# DDRSS0_CTL_CFG register map
Vendor: Texas Instruments
Registers are 32-bit, read-write, reset 0x0 unless marked. A register's access mark holds for its fields unless they carry their own. Offsets are as the file gives them; [hi:lo] are bit positions; lines under a group give offsets from that group; {n}, {i} and the like mark numbered series; 'fields as' and 'values as' point back to an identical list.

## DDRSS0_CTL_CFG (part 2 of 2)
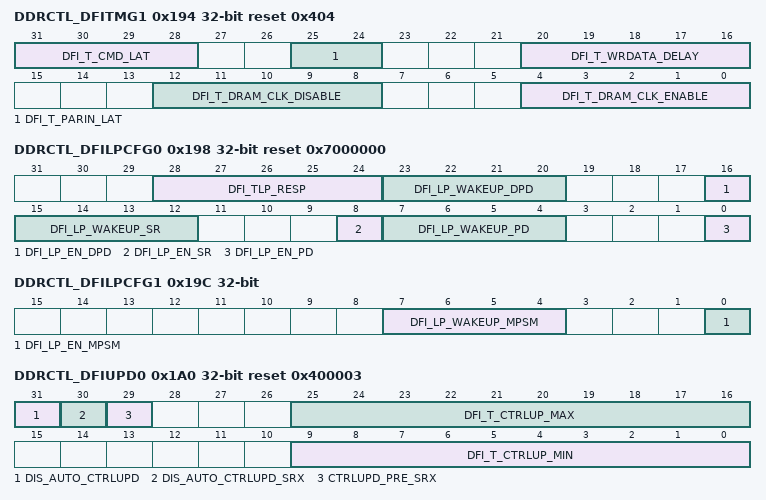
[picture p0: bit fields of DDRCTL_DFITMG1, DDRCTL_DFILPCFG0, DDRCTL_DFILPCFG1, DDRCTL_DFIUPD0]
0x194 DDRCTL_DFITMG1 reset 0x404 — DFI Timing Register 1
  [31:28] DFI_T_CMD_LAT — Specifies the number of 2 x DDRSS_CTL_CLK clock cycles between when the dfi_cs signal is asserted and when the associated command is driven.
  [25:24] DFI_T_PARIN_LAT — Specifies the number of 2 x DDRSS_CTL_CLK clock cycles between when the dfi_cs signal is asserted and when the associated dfi_parity_in signal is driven.
  [20:16] DFI_T_WRDATA_DELAY — Specifies the number of DDRSS_CTL_CLK clock cycles between when the dfi_wrdata_en signal is asserted and when the corresponding write data transfer is completed on the DRAM bus.
  [12:8] DFI_T_DRAM_CLK_DISABLE — Specifies the number of DDRSS_CTL_CLK clock cycles from the assertion of the dfi_dram_clk_disable signal on the DFI until the clock to the DRAM memory devices, at the PHY-DRAM boundary, maintains a low value.
  [4:0] DFI_T_DRAM_CLK_ENABLE — Specifies the number of DDRSS_CTL_CLK clock cycles from the de-assertion of the dfi_dram_clk_disable signal on the DFI until the first valid rising edge of the clock to the DRAM memory devices, at the PHY-DRAM boundary.
0x198 DDRCTL_DFILPCFG0 reset 0x7000000 — DFI Low Power Configuration Register 0
  [28:24] DFI_TLP_RESP — Setting in DDRSS_CTL_CLK clock cycles for DFI's tlp_resp time.
  [23:20] DFI_LP_WAKEUP_DPD — Value in DDRSS_CTL_CLK clock cycles to drive on dfi_lp_wakeup signal when Deep Power Down mode is entered.This is only present for designs supporting mDDR or LPDDR2/LPDDR3 devices.
  [16] DFI_LP_EN_DPD — Enables DFI Low Power interface handshaking during Deep Power Down Entry/Exit.This is only present for designs supporting mDDR or LPDDR2/LPDDR3 devices.
  [15:12] DFI_LP_WAKEUP_SR — Value in DFI clpck cycles to drive on dfi_lp_wakeup signal when Self Refresh mode is entered.
  [8] DFI_LP_EN_SR — Enables DFI Low Power interface handshaking during Self Refresh Entry/Exit.
  [7:4] DFI_LP_WAKEUP_PD — Value in DDRSS_CTL_CLK clock cycles to drive on dfi_lp_wakeup signal when Power Down mode is entered.
  [0] DFI_LP_EN_PD — Enables DFI Low Power interface handshaking during Power Down Entry/Exit.
0x19C DDRCTL_DFILPCFG1 — DFI Low Power Configuration Register 1
  [7:4] DFI_LP_WAKEUP_MPSM — Value in DDRSS_CTL_CLK clock cycles to drive on dfi_lp_wakeup signal when Maximum Power Saving Mode is entered.This is only present for designs supporting DDR4 devices.
  [0] DFI_LP_EN_MPSM — Enables DFI Low Power interface handshaking during Maximum Power Saving Mode Entry/Exit.
0x1A0 DDRCTL_DFIUPD0 reset 0x400003 — DFI Update Register 0
  [31] DIS_AUTO_CTRLUPD — When '1', disable the automatic dfi_ctrlupd_req generation by the DDR controller.
  [30] DIS_AUTO_CTRLUPD_SRX — When '1', disable the automatic dfi_ctrlupd_req generation by the DDR controller at self-refresh exit.
  [29] CTRLUPD_PRE_SRX — Selects dfi_ctrlupd_req requirements at SRX:0 - send ctrlupd after SRX1 - send ctrlupd before SRX If DDRCTL_DFIUPD0.dis_auto_ctrlupd_srx=1, this register has no impact, because no dfi_ctrlupd_req will be issued when SRX.
  [25:16] DFI_T_CTRLUP_MAX — Specifies the maximum number of DDRSS_CTL_CLK clock cycles that the dfi_ctrlupd_req signal can assert.
  [9:0] DFI_T_CTRLUP_MIN — Specifies the minimum number of DDRSS_CTL_CLK clock cycles that the dfi_ctrlupd_req signal must be asserted.
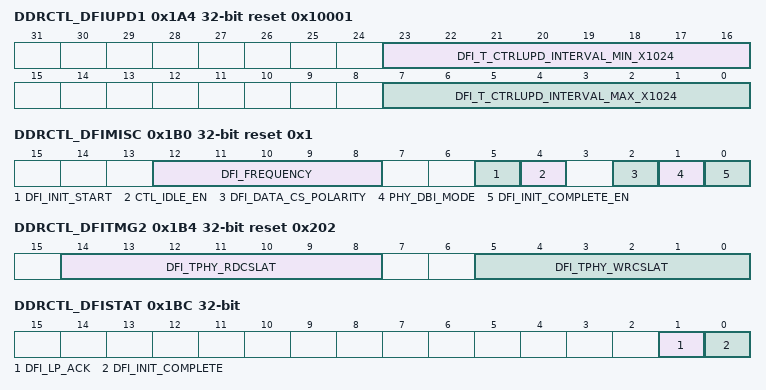
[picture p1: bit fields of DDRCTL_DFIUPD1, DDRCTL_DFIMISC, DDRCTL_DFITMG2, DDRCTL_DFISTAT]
0x1A4 DDRCTL_DFIUPD1 reset 0x10001 — DFI Update Register 1
  [23:16] DFI_T_CTRLUPD_INTERVAL_MIN_X1024 — This is the minimum amount of time between DDR controller initiated DFI update requests (which is executed whenever the DDR controller is idle).
  [7:0] DFI_T_CTRLUPD_INTERVAL_MAX_X1024 — This is the maximum amount of time between DDR controller initiated DFI update requests.
0x1A8 DDRCTL_DFIUPD2 reset 0x80000000 — DFI Update Register 2
  [31] DFI_PHYUPD_EN — Enables the support for acknowledging PHY-initiated updates:
0x1B0 DDRCTL_DFIMISC reset 0x1 — DFI Miscellaneous Control Register
  [12:8] DFI_FREQUENCY — Indicates the operating frequency of the system.
  [5] DFI_INIT_START — PHY init start request signal.
  [4] CTL_IDLE_EN — Enables support of ctl_idle signal, which is non-DFI related pin.
  [2] DFI_DATA_CS_POLARITY — Defines polarity of dfi_wrdata_cs and dfi_rddata_cs signals.0 - Signals are active low1 - Signals are active high
  [1] PHY_DBI_MODE — DBI implemented in DDRC or PHY.Present only in designs configured to support DDR4 and LPDDR4.
  [0] DFI_INIT_COMPLETE_EN — PHY initialization complete enable signal.
0x1B4 DDRCTL_DFITMG2 reset 0x202 — DFI Timing Register 2
  [14:8] DFI_TPHY_RDCSLAT — Number of 2 x DDRSS_CTL_CLK clock cycles between when a read command is sent on the DFI control interface and when the associated dfi_rddata_cs signal is asserted.
  [5:0] DFI_TPHY_WRCSLAT — Number of 2 x DDRSS_CTL_CLK clock cycles between when a write command is sent on the DFI control interface and when the associated dfi_wrdata_cs signal is asserted.
0x1B8 DDRCTL_DFITMG3 — DFI Timing Register 3
  [4:0] DFI_T_GEARDOWN_DELAY — The delay from dfi_geardown_en assertion to the time of the PHY being ready to receive commands.
0x1BC DDRCTL_DFISTAT ro — DFI Status Register
  [1] DFI_LP_ACK — Stores the value of the dfi_lp_ack input to the controller.
  [0] DFI_INIT_COMPLETE — The status flag register which announces when the DFI initialization has been completed.
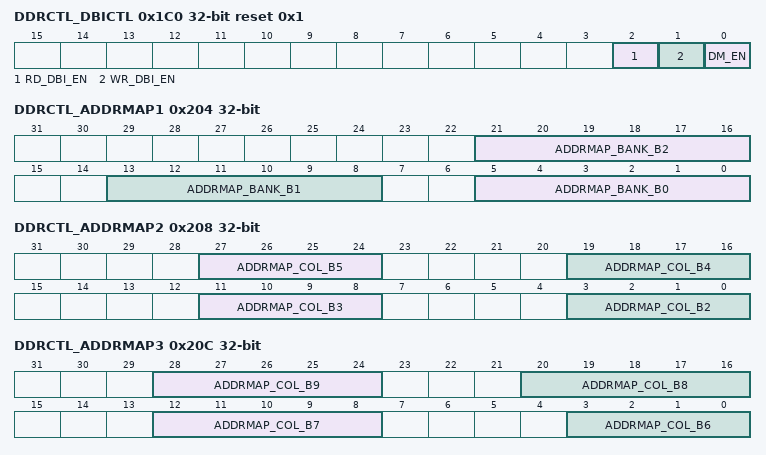
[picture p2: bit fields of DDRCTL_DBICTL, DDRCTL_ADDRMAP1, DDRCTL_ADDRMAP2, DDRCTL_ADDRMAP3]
0x1C0 DDRCTL_DBICTL reset 0x1 — DM/DBI Control Register
  [2] RD_DBI_EN — Read DBI enable signal in DDRC.
  [1] WR_DBI_EN — Write DBI enable signal in DDRC.
  [0] DM_EN — DM enable signal in DDRC.
0x1C4 DDRCTL_DFIPHYMSTR reset 0x1 — DFI PHY Master
  [0] DFI_PHYMSTR_EN — Enables the PHY Master Interface:
0x200 DDRCTL_ADDRMAP0 — Address Map Register 0
  [4:0] ADDRMAP_CS_BIT0 — Selects the HIF address bit used as rank address bit 0.Internal Base: 6The selected HIF address bit is determined by adding the internal base to the value of this field. If unused, set to 31 and then rank address bit 0 is set to 0.
0x204 DDRCTL_ADDRMAP1 — Address Map Register 1
  [21:16] ADDRMAP_BANK_B2 — Selects the HIF address bit used as bank address bit 2.The selected HIF address bit is determined by adding the internal base to the value of this field. If unused, set to 63 and then bank address bit 2 is set to 0.
  [13:8] ADDRMAP_BANK_B1 — Selects the HIF address bits used as bank address bit 1.The selected HIF address bit for each of the bank address bits is determined by adding the internal base to the value of this field. If unused, set to 63 and then bank address bit 1 is set to 0.
  [5:0] ADDRMAP_BANK_B0 — Selects the HIF address bits used as bank address bit 0.The selected HIF address bit for each of the bank address bits is determined by adding the internal base to the value of this field. If unused, set to 63 and then bank address bit 0 is set to 0.
0x208 DDRCTL_ADDRMAP2 — Address Map Register 2
  [27:24] ADDRMAP_COL_B5 — - Full bus width mode: Selects the HIF address bit used as column address bit 5.- Quarter bus width mode: Selects the HIF address bit used as column address bit 7.Valid Range: 0 to 7, and 15Internal Base: 5The selected HIF address bit is determined by adding the internal base to the value of this field. If unused, set to 15 and then this column address bit is set to 0.
  [19:16] ADDRMAP_COL_B4 — - Full bus width mode: Selects the HIF address bit used as column address bit 4.- Quarter bus width mode: Selects the HIF address bit used as column address bit 6.Valid Range: 0 to 7, and 15Internal Base: 4The selected HIF address bit is determined by adding the internal base to the value of this field. If unused, set to 15 and then this column address bit is set to 0.
  [11:8] ADDRMAP_COL_B3 — - Full bus width mode: Selects the HIF address bit used as column address bit 3.- Quarter bus width mode: Selects the HIF address bit used as column address bit 5.Valid Range: 0 to 7Internal Base: 3The selected HIF address bit is determined by adding the internal base to the value of this field.
  [3:0] ADDRMAP_COL_B2 — - Full bus width mode: Selects the HIF address bit used as column address bit 2.- Quarter bus width mode: Selects the HIF address bit used as column address bit 4.Valid Range: 0 to 7Internal Base: 2The selected HIF address bit is determined by adding the internal base to the value of this field.
0x20C DDRCTL_ADDRMAP3 — Address Map Register 3
  [28:24] ADDRMAP_COL_B9 — - Full bus width mode: Selects the HIF address bit used as column address bit 9.- Quarter bus width mode: Selects the HIF address bit used as column address bit 13 (11 in LPDDR2/LPDDR3 mode).Valid Range: 0 to 7, x, and 31. x indicate a valid value in inline ECC configuration.Internal Base: 9The selected HIF address bit is determined by adding the internal base to the value of this field. If unused, set to 31 and then this column address bit is set to 0.
  [20:16] ADDRMAP_COL_B8 — - Full bus width mode: Selects the HIF address bit used as column address bit 8.- Quarter bus width mode: Selects the HIF address bit used as column address bit 11 (10 in LPDDR2/LPDDR3 mode).Valid Range: 0 to 7, x, and 31. x indicate a valid value in inline ECC configuration.Internal Base: 8The selected HIF address bit is determined by adding the internal base to the value of this field. If unused, set to 31 and then this column address bit is set to 0.
  [12:8] ADDRMAP_COL_B7 — - Full bus width mode: Selects the HIF address bit used as column address bit 7.- Quarter bus width mode: Selects the HIF address bit used as column address bit 9.Internal Base: 7The selected HIF address bit is determined by adding the internal base to the value of this field. If unused, set to 31 and then this column address bit is set to 0. In Inline ECC configuration and ECC is enabled (DDRCTL_ECCCFG0.ecc_mode&gt;0), the highest 3 column address bits must map to the highest 3 valid HIF address bits. If column bit 7 is the third highest column address bit, it must map to the third highest valid HIF address bit. (x = the highest valid HIF address bit - 2 - internal base) if it is unused, set to 31.
  [3:0] ADDRMAP_COL_B6 — - Full bus width mode: Selects the HIF address bit used as column address bit 6.- Quarter bus width mode: Selects the HIF address bit used as column address bit 8.Valid Range: 0 to 7, and 15Internal Base: 6The selected HIF address bit is determined by adding the internal base to the value of this field. If unused, set to 15 and then this column address bit is set to 0.
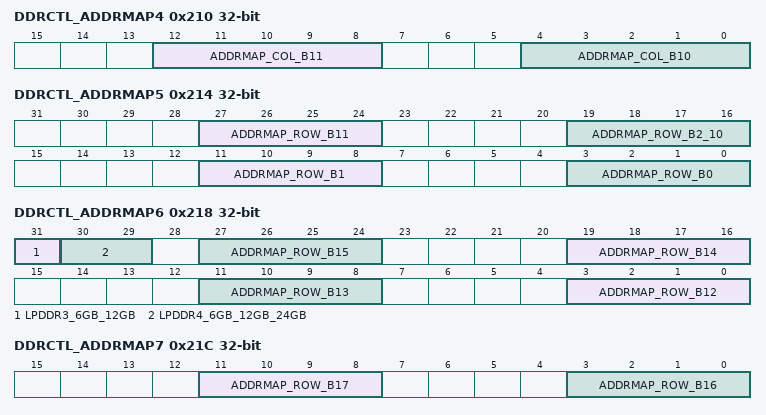
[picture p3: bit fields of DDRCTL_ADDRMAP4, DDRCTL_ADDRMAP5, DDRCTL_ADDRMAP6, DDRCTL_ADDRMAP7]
0x210 DDRCTL_ADDRMAP4 — Address Map Register 4
  [12:8] ADDRMAP_COL_B11 — - Full bus width mode: Selects the HIF address bit used as column address bit 13 (11 in LPDDR2/LPDDR3 mode).- Quarter bus width mode: Unused. To make it unused, this must be tied to 4'hF.Valid Range: 0 to 7, x, and 31. x indicate a valid value in inline ECC configuration.Internal Base: 11The selected HIF address bit is determined by adding the internal base to the value of this field. If unused, set to 31 and then this column address bit is set to 0.
  [4:0] ADDRMAP_COL_B10 — - Full bus width mode: Selects the HIF address bit used as column address bit 11 (10 in LPDDR2/LPDDR3 mode).- Quarter bus width mode: UNUSED. To make it unused, this must be tied to 4'hF.Valid Range: 0 to 7, x, and 31. x indicate a valid value in inline ECC configuration.The selected HIF address bit is determined by adding the internal base to the value of this field. If unused, set to 31 and then this column address bit is set to 0.
0x214 DDRCTL_ADDRMAP5 — Address Map Register 5
  [27:24] ADDRMAP_ROW_B11 — Selects the HIF address bit used as row address bit 11.The selected HIF address bit is determined by adding the internal base to the value of this field. If unused, set to 15 and then row address bit 11 is set to 0.
  [19:16] ADDRMAP_ROW_B2_10 — Selects the HIF address bits used as row address bits 2 to 10.Internal Base: 8 (for row address bit 2), 9 (for row address bit 3), 10 (for row address bit 4) etc increasing to 16 (for row address bit 10)The selected HIF address bit for each of the row address bits is determined by adding the internal base to the value of this field.
  [11:8] ADDRMAP_ROW_B1 — Selects the HIF address bits used as row address bit 1.Internal Base: 7The selected HIF address bit for each of the row address bits is determined by adding the internal base to the value of this field.
  [3:0] ADDRMAP_ROW_B0 — Selects the HIF address bits used as row address bit 0.Internal Base: 6The selected HIF address bit for each of the row address bits is determined by adding the internal base to the value of this field.
0x218 DDRCTL_ADDRMAP6 — Address Map Register 6
  [31] LPDDR3_6GB_12GB — Set this to 1 if there is an LPDDR3 SDRAM 6Gb or 12Gb device in use.
  [30:29] LPDDR4_6GB_12GB_24GB — Indicates what type of LPDDR4 SDRAM device is in use.
  [8n-93:8n-96] ADDRMAP_ROW_B{n} (n=12..15) — Selects the HIF address bit used as row address bit {n}.
0x21C DDRCTL_ADDRMAP7 — Address Map Register 7
  [11:8] ADDRMAP_ROW_B17 — Selects the HIF address bit used as row address bit 17.
  [3:0] ADDRMAP_ROW_B16 — Selects the HIF address bit used as row address bit 16.
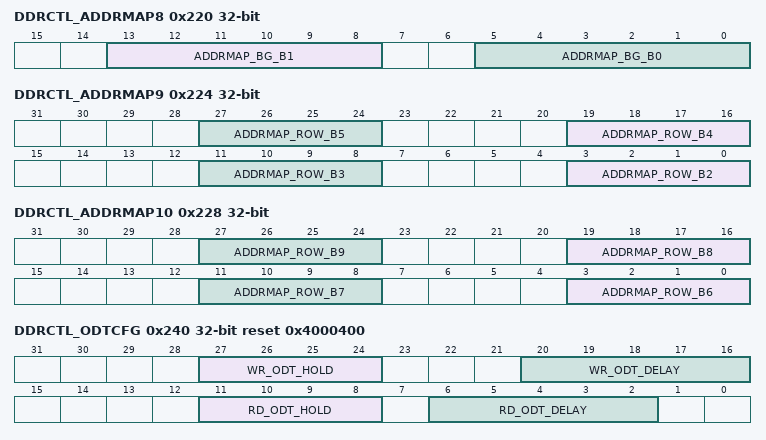
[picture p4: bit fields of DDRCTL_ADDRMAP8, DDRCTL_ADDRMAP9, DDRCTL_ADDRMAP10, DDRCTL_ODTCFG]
0x220 DDRCTL_ADDRMAP8 — Address Map Register 8
  [13:8] ADDRMAP_BG_B1 — Selects the HIF address bits used as bank group address bit 1.
  [5:0] ADDRMAP_BG_B0 — Selects the HIF address bits used as bank group address bit 0.
0x224 DDRCTL_ADDRMAP9 — Address Map Register 9
  [8n-13:8n-16] ADDRMAP_ROW_B{n} (n=2..5) — Selects the HIF address bits used as row address bit {n}.
0x228 DDRCTL_ADDRMAP10 — Address Map Register 10
  [8n-45:8n-48] ADDRMAP_ROW_B{n} (n=6..9) — Selects the HIF address bits used as row address bit {n}.
0x22C DDRCTL_ADDRMAP11 — Address Map Register 11
  [3:0] ADDRMAP_ROW_B10 — Selects the HIF address bits used as row address bit 10.
0x240 DDRCTL_ODTCFG reset 0x4000400 — ODT Configuration Register
  [27:24] WR_ODT_HOLD — 2 x DDRSS_CTL_CLK clock cycles to hold ODT for a write command.DDR2:- BL8: 0x5 (DDR2-400/533/667), 0x6 (DDR2-800), 0x7 (DDR2-1066)- BL4: 0x3 (DDR2-400/533/667), 0x4 (DDR2-800), 0x5 (DDR2-1066)DDR3:- BL8: 0x6DDR4:- BL8: 5 + WR_PREAMBLE + CRC_MODE WR_PREAMBLE = 1 (1tCK write preamble), 2 (2tCK write preamble) CRC_MODE = 0 (not CRC mode), 1 (CRC mode)LPDDR3:- BL8: 7 + RU(tODTon(max)/tCK)
  [20:16] WR_ODT_DELAY — The delay, in 2 x DDRSS_CTL_CLK clock cycles, from issuing a write command to setting ODT values associated with that command.DDR2:- CWL + AL - 3 (DDR2-400/533/667)- CWL + AL - 4 (DDR2-800)- CWL + AL - 5 (DDR2-1066)If (CWL + AL - 3 &lt; 0), DDR controller does not support ODT for write operation.DDR3: 0x0DDR4: DDRCTL_DFITMG1.dfi_t_cmd_lat (to adjust for CAL mode)LPDDR3: WL - 1 - RU(tODTon(max)/tCK)
  [11:8] RD_ODT_HOLD — 2 x DDRSS_CTL_CLK clock cycles to hold ODT for a read command.DDR2:- BL8: 0x6 (not DDR2-1066), 0x7 (DDR2-1066)- BL4: 0x4 (not DDR2-1066), 0x5 (DDR2-1066)DDR3:- BL8: 0x6DDR4:- BL8: 5 + RD_PREAMBLE RD_PREAMBLE = 1 (1tCK write preamble), 2 (2tCK write preamble)LPDDR3:- BL8: 5 + RU(tDQSCK(max)/tCK) - RD(tDQSCK(min)/tCK) + RU(tODTon(max)/tCK)
  [6:2] RD_ODT_DELAY — The delay, in 2 x DDRSS_CTL_CLK clock cycles, from issuing a read command to setting ODT values associated with that command.DDR2:- CL + AL - 4 (not DDR2-1066),- CL + AL - 5 (DDR2-1066)If (CL + AL - 4 &lt; 0), DDR controller does not support ODT for read operation.DDR3: CL - CWLDDR4: CL - CWL - RD_PREAMBLE + WR_PREAMBLE + DDRCTL_DFITMG1.dfi_t_cmd_lat (to adjust for CAL mode) WR_PREAMBLE = 1 (1tCK write preamble), 2 (2tCK write preamble) RD_PREAMBLE = 1 (1tCK write preamble), 2 (2tCK write preamble).If (CL - CWL - RD_PREAMBLE + WR_PREAMBLE) &lt; 0, DDR controller does not support ODT for read operation.LPDDR3: RL + RD(tDQSCK(min)/tCK) - 1 - RU(tODTon(max)/tCK)
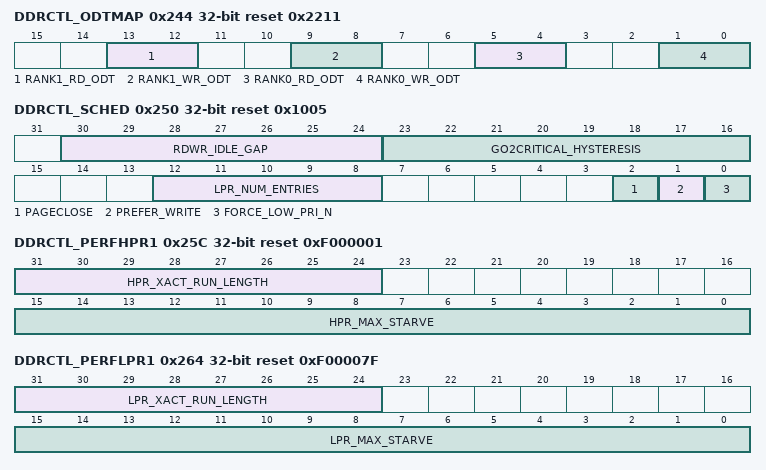
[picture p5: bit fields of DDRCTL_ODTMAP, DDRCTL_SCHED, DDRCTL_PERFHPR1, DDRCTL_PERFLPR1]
0x244 DDRCTL_ODTMAP reset 0x2211 — ODT/Rank Map Register
  [13:12] RANK1_RD_ODT — Indicates which remote ODTs must be turned on during a read from rank 1.
  [9:8] RANK1_WR_ODT — Indicates which remote ODTs must be turned on during a write to rank 1.
  [5:4] RANK0_RD_ODT — Indicates which remote ODTs must be turned on during a read from rank 0.
  [1:0] RANK0_WR_ODT — Indicates which remote ODTs must be turned on during a write to rank 0.
0x250 DDRCTL_SCHED reset 0x1005 — Scheduler Control Register
  [30:24] RDWR_IDLE_GAP — When the preferred transaction store is empty for these many clock cycles, switch to the alternate transaction store if it is non-empty.
  [23:16] GO2CRITICAL_HYSTERESIS — UNUSED
  [12:8] LPR_NUM_ENTRIES — Number of entries in the low priority transaction store is this value + 1.
  [2] PAGECLOSE — If true, bank is kept open only while there are page hit transactions available in the CAM to that bank.
  [1] PREFER_WRITE — If set then the bank selector prefers writes over reads.
  [0] FORCE_LOW_PRI_N — Active low signal.
0x254 DDRCTL_SCHED1 — Scheduler Control Register 1
  [7:0] PAGECLOSE_TIMER — This field works in conjunction with DDRCTL_SCHED.pageclose. It only has meaning if DDRCTL_SCHED.pageclose==1. If DDRCTL_SCHED.pageclose==1 and pageclose_timer==0, then an auto-precharge may be scheduled for last read or write command in the CAM with a bank and page hit.
0x25C DDRCTL_PERFHPR1 reset 0xF000001 — High Priority Read CAM Register 1
  [31:24] HPR_XACT_RUN_LENGTH — Number of transactions that are serviced once the HPR queue goes critical is the smaller of:- (a) This number- (b) Number of transactions available.
  [15:0] HPR_MAX_STARVE — Number of DDRSS_CTL_CLK clock cycles that the HPR queue can be starved before it goes critical.
0x264 DDRCTL_PERFLPR1 reset 0xF00007F — Low Priority Read CAM Register 1
  [31:24] LPR_XACT_RUN_LENGTH — Number of transactions that are serviced once the LPR queue goes critical is the smaller of:- (a) This number- (b) Number of transactions available.
  [15:0] LPR_MAX_STARVE — Number of DDRSS_CTL_CLK clock cycles that the LPR queue can be starved before it goes critical.
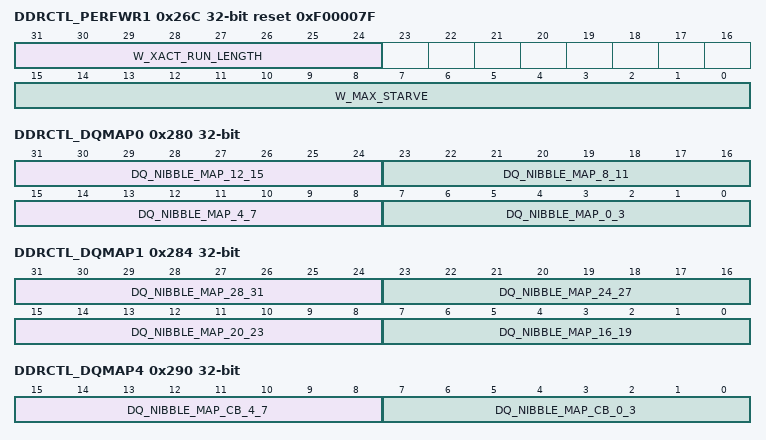
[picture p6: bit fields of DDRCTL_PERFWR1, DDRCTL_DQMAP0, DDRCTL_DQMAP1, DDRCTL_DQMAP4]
0x26C DDRCTL_PERFWR1 reset 0xF00007F — Write CAM Register 1
  [31:24] W_XACT_RUN_LENGTH — Number of transactions that are serviced once the WR queue goes critical is the smaller of:- (a) This number- (b) Number of transactions available.
  [15:0] W_MAX_STARVE — Number of DDRSS_CTL_CLK clock cycles that the WR queue can be starved before it goes critical.
0x280 DDRCTL_DQMAP0 — DQ Map Register 0
  [31:24] DQ_NIBBLE_MAP_12_15 — DQ nibble map for DQ bits [12-15] Present only in designs configured to support DDR4.
  [23:16] DQ_NIBBLE_MAP_8_11 — DQ nibble map for DQ bits [8-11] Present only in designs configured to support DDR4.
  [15:8] DQ_NIBBLE_MAP_4_7 — DQ nibble map for DQ bits [4-7] Present only in designs configured to support DDR4.
  [7:0] DQ_NIBBLE_MAP_0_3 — DQ nibble map for DQ bits [0-3] Present only in designs configured to support DDR4.
0x284 DDRCTL_DQMAP1 — DQ Map Register 1
  [31:24] DQ_NIBBLE_MAP_28_31 — DQ nibble map for DQ bits [28-31] Present only in designs configured to support DDR4.
  [23:16] DQ_NIBBLE_MAP_24_27 — DQ nibble map for DQ bits [24-27] Present only in designs configured to support DDR4.
  [15:8] DQ_NIBBLE_MAP_20_23 — DQ nibble map for DQ bits [20-23] Present only in designs configured to support DDR4.
  [7:0] DQ_NIBBLE_MAP_16_19 — DQ nibble map for DQ bits [16-19] Present only in designs configured to support DDR4.
0x290 DDRCTL_DQMAP4 — DQ Map Register 4
  [15:8] DQ_NIBBLE_MAP_CB_4_7 — DQ nibble map for DIMM ECC check bits [4-7] Present only in designs configured to support DDR4.
  [7:0] DQ_NIBBLE_MAP_CB_0_3 — DQ nibble map for DIMM ECC check bits [0-3] Present only in designs configured to support DDR4.
0x294 DDRCTL_DQMAP5 — DQ Map Register 5
  [0] DIS_DQ_RANK_SWAP — All even ranks have the same DQ mapping controled by DQMAP0-4 register as rank 0.1 - Disable rank based DQ swapping0 - Enable rank based DQ swapping Present only in designs configured to support DDR4.
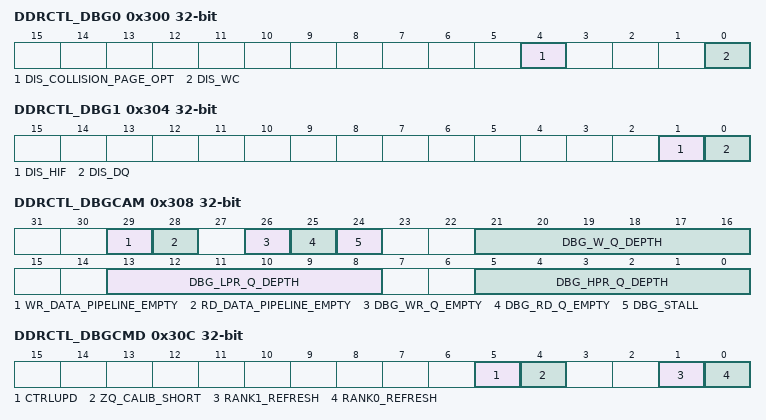
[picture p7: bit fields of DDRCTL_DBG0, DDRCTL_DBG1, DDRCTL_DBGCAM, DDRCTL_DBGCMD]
0x300 DDRCTL_DBG0 — Debug Register 0
  [4] DIS_COLLISION_PAGE_OPT — When this is set to '0', auto-precharge is disabled for the flushed command in a collision case.
  [0] DIS_WC — When 1, disable write combine.
0x304 DDRCTL_DBG1 — Debug Register 1
  [1] DIS_HIF — When 1, DDR controller asserts the HIF command signal hif_cmd_stall.
  [0] DIS_DQ — When 1, DDR controller will not de-queue any transactions from the CAM.
0x308 DDRCTL_DBGCAM ro — CAM Debug Register
  [29] WR_DATA_PIPELINE_EMPTY — This bit indicates that the write data pipeline on the DFI interface is empty.
  [28] RD_DATA_PIPELINE_EMPTY — This bit indicates that the read data pipeline on the DFI interface is empty.
  [26] DBG_WR_Q_EMPTY — When 1, all the Write command queues and Write data buffers inside DDRC are empty.
  [25] DBG_RD_Q_EMPTY — When 1, all the Read command queues and Read data buffers inside DDRC are empty.
  [24] DBG_STALL — Stall FOR DEBUG ONLY
  [21:16] DBG_W_Q_DEPTH — Write queue depth The last entry of WR queue is reserved for ECC SCRUB operation.
  [13:8] DBG_LPR_Q_DEPTH — Low priority read queue depth The last entry of Lpr queue is reserved for ECC SCRUB operation.
  [5:0] DBG_HPR_Q_DEPTH — High priority read queue depth FOR DEBUG ONLY
0x30C DDRCTL_DBGCMD access not given — Command Debug Register
  [5] CTRLUPD — Setting this register bit to 1 indicates to the DDR controller to issue a dfi_ctrlupd_req to the PHY. (access W1S)
  [4] ZQ_CALIB_SHORT — Setting this register bit to 1 indicates to the DDR controller to issue a ZQCS (ZQ calibration short)/MPC(ZQ calibration) command to the SDRAM. (access W1S)
  [1] RANK1_REFRESH — Setting this register bit to 1 indicates to the DDR controller to issue a refresh to rank 1. (access W1S)
  [0] RANK0_REFRESH — Setting this register bit to 1 indicates to the DDR controller to issue a refresh to rank 0. (access W1S)
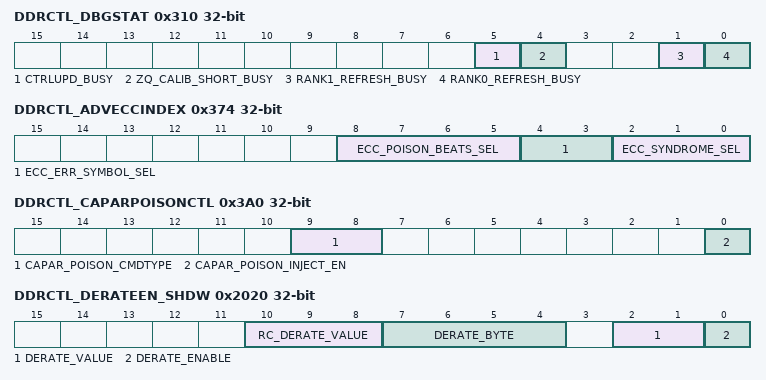
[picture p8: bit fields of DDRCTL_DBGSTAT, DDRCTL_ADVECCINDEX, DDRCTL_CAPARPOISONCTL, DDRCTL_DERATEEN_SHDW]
0x310 DDRCTL_DBGSTAT ro — Status Debug Register
  [5] CTRLUPD_BUSY — SoC core may initiate a ctrlupd operation only if this signal is low.
  [4] ZQ_CALIB_SHORT_BUSY — SoC core may initiate a ZQCS (ZQ calibration short) operation only if this signal is low.
  [1] RANK1_REFRESH_BUSY — SoC core may initiate a rank1_refresh operation (refresh operation to rank 1) only if this signal is low.
  [0] RANK0_REFRESH_BUSY — SoC core may initiate a rank0_refresh operation (refresh operation to rank 0) only if this signal is low.
0x320 DDRCTL_SWCTL reset 0x1 — Software Register Programming Control Enable
  [0] SW_DONE — Enable quasi-dynamic register programming outside reset.
0x324 DDRCTL_SWSTAT ro reset 0x1 — Software Register Programming Control Status
  [0] SW_DONE_ACK — Register programming done.
0x374 DDRCTL_ADVECCINDEX — Advanced ECC Index Register
  [8:5] ECC_POISON_BEATS_SEL — Selector of which DRAM beat's poison pattern will be set by DDRCTL_ECCPOISONPAT0/1/2 registers.4 DRAM beats can be poisoned. Set ecc_poison_beats_sel from 0~3 to set 1st to 4th beat's poison pattern. The other value is reserved.
  [4:3] ECC_ERR_SYMBOL_SEL — Selector of which error symbol's status output to ADVECCSTAT.
  [2:0] ECC_SYNDROME_SEL — Selector of which DRAM beat data output to DDRCTL_ECCCSYN0/1/2 as well as ECCUCSYN.
0x37C DDRCTL_ECCPOISONPAT0 — ECC Poison Pattern 0 Register
  [31:0] ECC_POISON_DATA_31_0 — Poison pattern for DRAM data[31:0].
0x384 DDRCTL_ECCPOISONPAT2 — ECC Poison Pattern 2 Register
  [7:0] ECC_POISON_DATA_71_64 — Poison pattern for DRAM data [71:64].
0x3A0 DDRCTL_CAPARPOISONCTL — CA parity poison contrl Register
  [9:8] CAPAR_POISON_CMDTYPE — Command type to be poisoned.
  [0] CAPAR_POISON_INJECT_EN — Setting this register bit to 1 triggers the CA parity poisoning.
0x3A4 DDRCTL_CAPARPOISONSTAT ro — CA parity poison status Register
  [0] CAPAR_POISON_COMPLETE — Indicates CA parity poisoning operation is done.
0x2020 DDRCTL_DERATEEN_SHDW — [FREQ1] Temperature Derate Enable Register
  [10:8] RC_DERATE_VALUE — Derate value of tRC for LPDDR4Present only in designs configured to support LPDDR4. The required number of cycles for derating can be determined by dividing 3.75ns by the core_ddrc_core_clk period, and rounding up the next integer.
  [7:4] DERATE_BYTE — Derate bytePresent only in designs configured to support LPDDR2/LPDDR3/LPDDR4. Indicates which byte of the MRR data is used for derating.
  [2:1] DERATE_VALUE — Derate valuePresent only in designs configured to support LPDDR2/LPDDR3/LPDDR4. Set to 0 for all LPDDR2 speed grades as derating value of +1.875 ns is less than a core_ddrc_core_clk period. For LPDDR3/4, if the period of core_ddrc_core_clk is less than 1.875ns, this register field should be set to 1 otherwise it should be set to 0.
  [0] DERATE_ENABLE — Enables derating
0x2024 DDRCTL_DERATEINT_SHDW reset 0x800000 — [FREQ1] Temperature Derate Interval Register
  [31:0] MR4_READ_INTERVAL — Interval between two MR4 reads, used to derate the timing parameters.
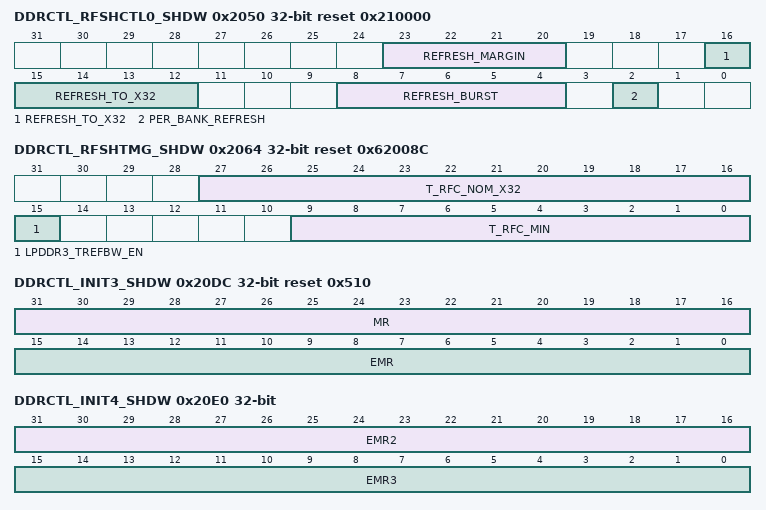
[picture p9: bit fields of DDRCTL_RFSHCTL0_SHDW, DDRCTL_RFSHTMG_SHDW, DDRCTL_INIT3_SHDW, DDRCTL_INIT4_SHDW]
0x2050 DDRCTL_RFSHCTL0_SHDW reset 0x210000 — [FREQ1] Refresh Control Register 0
  [23:20] REFRESH_MARGIN — Threshold value in number of DDRSS_CTL_CLK clock cycles before the critical refresh or page timer expires.
  [16:12] REFRESH_TO_X32 — If the refresh timer (tRFCnom, also known as tREFI) has expired at least once, but it has not expired (DDRCTL_RFSHCTL0.refresh_burst+1) times yet, then a speculative refresh may be performed. A speculative refresh is a refresh performed at a time when refresh would be useful, but before it is absolutely required.
  [8:4] REFRESH_BURST — The programmed value + 1 is the number of refresh timeouts that is allowed to accumulate before traffic is blocked and the refreshes are forced to execute.For information on burst refresh feature refer to section 3.9 of DDR2 JEDEC specification - JESD79-2F.pdf. For DDR2/3, the refresh is always per-rank and not per-bank. The rank refresh can be accumulated over 8*tREFI cycles using the burst refresh feature. In DDR4 mode, according to Fine Granularity feature, 8 refreshes can be postponed in 1X mode, 16 refreshes in 2X mode and 32 refreshes in 4X mode. If using PHY-initiated updates, care must be taken in the setting of DDRCTL_RFSHCTL0.refresh_burst, to ensure that tRFCmax is not violated due to a PHY-initiated update occurring shortly before a refresh burst was due. In this situation, the refresh burst will be delayed until the PHY-initiated update is complete.
  [2] PER_BANK_REFRESH — 1 - Per bank refresh
0x2064 DDRCTL_RFSHTMG_SHDW reset 0x62008C — [FREQ1] Refresh Timing Register
  [27:16] T_RFC_NOM_X32 — tREFI: Average time interval between refreshes per rank (Specification: 7.8us for DDR2, DDR3 and DDR4. See JEDEC specification for mDDR, LPDDR2, LPDDR3 and LPDDR4).For LPDDR2/LPDDR3/LPDDR4:- if using all-bank refreshes (DDRCTL_RFSHCTL0.per_bank_refresh = 0), this register should be set to tREFIab- if using per-bank refreshes (DDRCTL_RFSHCTL0.per_bank_refresh = 1), this register should be set to tREFIpb- Non-DDR4 or DDR4 Fixed 1x mode: DDRCTL_RFSHTMG.t_rfc_nom_x32 must be less than or equal to 0xFFE.Unit: Multiples of 32 clocks.
  [15] LPDDR3_TREFBW_EN — Used only when LPDDR3 memory type is connected.
  [9:0] T_RFC_MIN — tRFC (min): Minimum time from refresh to refresh or activate.In LPDDR2/LPDDR3/LPDDR4 mode:- if using all-bank refreshes, the tRFCmin value in the above equations is equal to tRFCab- if using per-bank refreshes, the tRFCmin value in the above equations is equal to tRFCpbIn DDR4 mode, the tRFCmin value in the above equations is different depending on the refresh mode (fixed 1X,2X,4X) and the device density.The user should program the appropriate value from the spec based on the 'refresh_mode' and the device density that is used. Unit: Clocks.
0x20DC DDRCTL_INIT3_SHDW reset 0x510 — [FREQ1] SDRAM Initialization Register 3
  [31:16] MR — DDR2: Value to write to MR register. Bit 8 is for DLL and the setting here is ignored. The DDR controller sets this bit appropriately.DDR3/DDR4: Value loaded into MR0 register.mDDR: Value to write to MR register.LPDDR2/LPDDR3/LPDDR4 - Value to write to MR1 register
  [15:0] EMR — DDR2: Value to write to EMR register. Bits 9:7 are for OCD and the setting in this register is ignored. The DDR controller sets those bits appropriately.DDR3/DDR4: Value to write to MR1 register Set bit 7 to 0. If PHY-evaluation mode training is enabled, this bit is set appropriately by the DDR controller during write leveling.mDDR: Value to write to EMR register.LPDDR2/LPDDR3/LPDDR4 - Value to write to MR2 register
0x20E0 DDRCTL_INIT4_SHDW — [FREQ1] SDRAM Initialization Register 4
  [31:16] EMR2 — DDR2: Value to write to EMR2 register.DDR3/DDR4: Value to write to MR2 registerLPDDR2/LPDDR3/LPDDR4: Value to write to MR3 register mDDR: Unused
  [15:0] EMR3 — DDR2: Value to write to EMR3 register.DDR3/DDR4: Value to write to MR3 registermDDR/LPDDR2/LPDDR3: UnusedLPDDR4: Value to write to MR13 register
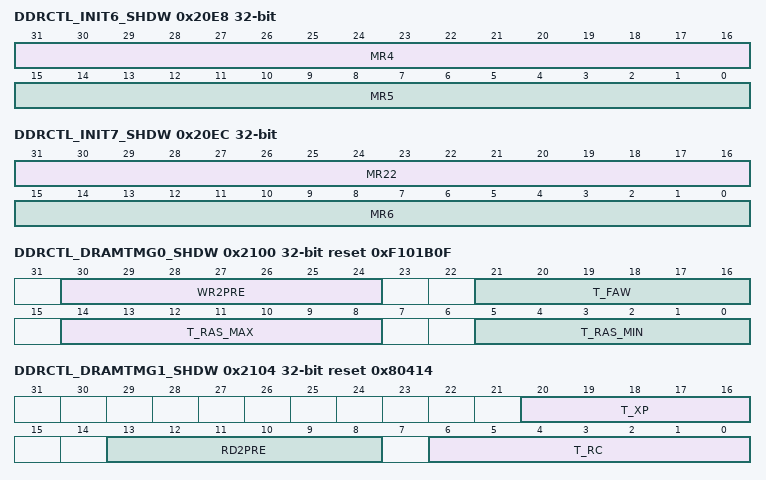
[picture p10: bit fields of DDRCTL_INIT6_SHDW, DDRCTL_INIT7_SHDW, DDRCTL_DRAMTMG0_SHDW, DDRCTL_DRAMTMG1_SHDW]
0x20E8 DDRCTL_INIT6_SHDW — [FREQ1] SDRAM Initialization Register 6
  [31:16] MR4 — DDR4 - Value to be loaded into SDRAM MR4 registers.
  [15:0] MR5 — DDR4 - Value to be loaded into SDRAM MR5 registers.
0x20EC DDRCTL_INIT7_SHDW — [FREQ1] SDRAM Initialization Register 7
  [31:16] MR22 — LPDDR4 - Value to be loaded into SDRAM MR22 registers.
  [15:0] MR6 — DDR4 - Value to be loaded into SDRAM MR6 registers.
0x2100 DDRCTL_DRAMTMG0_SHDW reset 0xF101B0F — [FREQ1] SDRAM Timing Register 0
  [30:24] WR2PRE — Minimum time between write and precharge to same bank.Specifications: WL + BL/2 + tWR = approximately 8 cycles + 15 ns = 14 clocks MHz and less for lower frequencies where:- WL = write latency- BL = burst length. This must match the value programmed in the BL bit of the mode register to the SDRAM. BST (burst terminate) is not supported at present.- tWR = Write recovery time. This comes directly from the SDRAM specification. Add one extra cycle for LPDDR2/LPDDR3/LPDDR4 for this parameter.
  [21:16] T_FAW — tFAW Valid only when 8 or more banks(or banks x bank groups) are present.
  [14:8] T_RAS_MAX — tRAS(max): Maximum time between activate and precharge to same bank.
  [5:0] T_RAS_MIN — tRAS(min): Minimum time between activate and precharge to the same bank.
0x2104 DDRCTL_DRAMTMG1_SHDW reset 0x80414 — [FREQ1] SDRAM Timing Register 1
  [20:16] T_XP — tXP: Minimum time after power-down exit to any operation.
  [13:8] RD2PRE — tRTP: Minimum time from read to precharge of same bank.Unit: Clocks.
  [6:0] T_RC — tRC: Minimum time between activates to same bank.
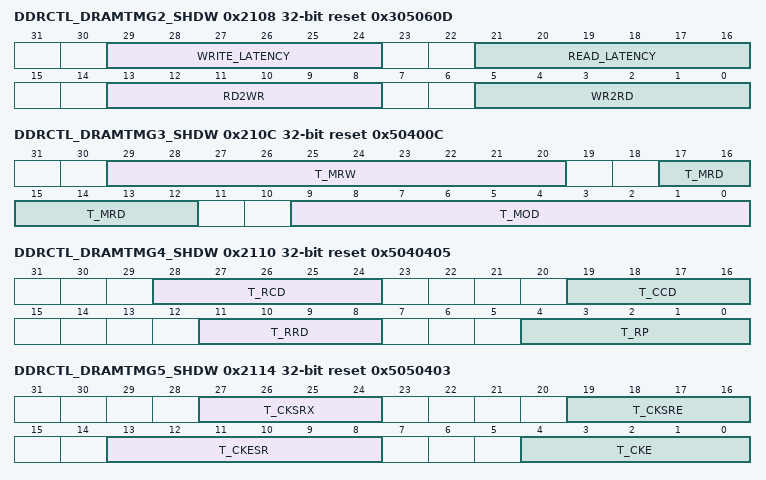
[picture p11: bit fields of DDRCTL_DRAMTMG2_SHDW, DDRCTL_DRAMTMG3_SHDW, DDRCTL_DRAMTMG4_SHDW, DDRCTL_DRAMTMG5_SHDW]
0x2108 DDRCTL_DRAMTMG2_SHDW reset 0x305060D — [FREQ1] SDRAM Timing Register 2
  [29:24] WRITE_LATENCY — Set to WL Time from write command to write data on SDRAM interface. This must be set to WL. For mDDR, it should normally be set to 1.
  [21:16] READ_LATENCY — Set to RL Time from read command to read data on SDRAM interface. This must be set to RL.
  [13:8] RD2WR — Minimum time from read command to write command.Include time for bus turnaround and all per-bank, per-rank, and global constraints.DDR2/3/mDDR: RL + BL/2 + 2 - WL DDR4: RL + BL/2 + 1 + WR_PREAMBLE - WLLPDDR2/LPDDR3: RL + BL/2 + RU(tDQSCKmax/tCK) + 1 - WL LPDDR4(DQ ODT is Disabled): RL + BL/2 + RU(tDQSCKmax/tCK) + WR_PREAMBLE + RD_POSTAMBLE - WLLPDDR4(DQ ODT is Enabled) : RL + BL/2 + RU(tDQSCKmax/tCK) + RD_POSTAMBLE - ODTLon - RU(tODTon(min)/tCK)Unit: Clocks.Where:- WL = write latency- BL = burst length. This must match the value programmed in the BL bit of the mode register to the SDRAM- RL = read latency = CAS latency - WR_PREAMBLE = write preamble. This is unique to DDR4 and LPDDR4.- RD_POSTAMBLE = read postamble. This is unique to LPDDR4. For LPDDR2/LPDDR3/LPDDR4, if derating is enabled (DDRCTL_DERATEEN.derate_enable=1), derated tDQSCKmax should be used.
  [5:0] WR2RD — In DDR4, minimum time from write command to read command for same bank group. In others, minimum time from write command to read command.Includes time for bus turnaround, recovery times, and all per-bank, per-rank, and global constraints.DDR4: CWL + PL + BL/2 + tWTR_LLPDDR2/3/4: WL + BL/2 + tWTR + 1Others: CWL + BL/2 + tWTRUnit: Clocks.Where:- CWL = CAS write latency- WL = Write latency- PL = Parity latency- BL = burst length. This must match the value programmed in the BL bit of the mode register to the SDRAM- tWTR_L = internal write to read command delay for same bank group. This comes directly from the SDRAM specification.- tWTR = internal write to read command delay. This comes directly from the SDRAM specification. Add one extra cycle for LPDDR2/LPDDR3/LPDDR4 operation.
0x210C DDRCTL_DRAMTMG3_SHDW reset 0x50400C — [FREQ1] SDRAM Timing Register 3
  [29:20] T_MRW — Time to wait after a mode register write or read (MRW or MRR).LPDDR2 typically requires value of 5.LPDDR3 typically requires value of 10.LPDDR4: Set this to the larger of tMRW and tMRWCKEL.For LPDDR2, this register is used for the time from a MRW/MRR to all other commands.
  [17:12] T_MRD — tMRD: Cycles to wait after a mode register write or read.DDR2/mDDR: Time from MRS to any commandDDR3/4: Time from MRS to MRS commandLPDDR2: not usedLPDDR3/4: Time from MRS to non-MRS command.
  [9:0] T_MOD — tMOD: Parameter used only in DDR3 and DDR4.
0x2110 DDRCTL_DRAMTMG4_SHDW reset 0x5040405 — [FREQ1] SDRAM Timing Register 4
  [28:24] T_RCD — tRCD - tAL: Minimum time from activate to read or write command to same bank.
  [19:16] T_CCD — DDR4: tCCD_L: This is the minimum time between two reads or two writes for same bank group.
  [11:8] T_RRD — DDR4: tRRD_L: Minimum time between activates from bank 'a' to bank 'b' for same bank group.
  [4:0] T_RP — tRP: Minimum time from precharge to activate of same bank.
0x2114 DDRCTL_DRAMTMG5_SHDW reset 0x5050403 — [FREQ1] SDRAM Timing Register 5
  [27:24] T_CKSRX — This is the time before Self Refresh Exit that CK is maintained as a valid clock before issuing SRX.
  [19:16] T_CKSRE — This is the time after Self Refresh Down Entry that CK is maintained as a valid clock.(*)Only if DDRCTL_CRCPARCTL1.caparity_disable_before_sr=0, this register should be increased by PL.
  [13:8] T_CKESR — Minimum CKE low width for Self refresh or Self refresh power down entry to exit timing in memory clock cycles.(*)Only if DDRCTL_CRCPARCTL1.caparity_disable_before_sr=0, this register should be increased by PL.
  [4:0] T_CKE — Minimum number of cycles of CKE HIGH/LOW during power-down and self refresh.
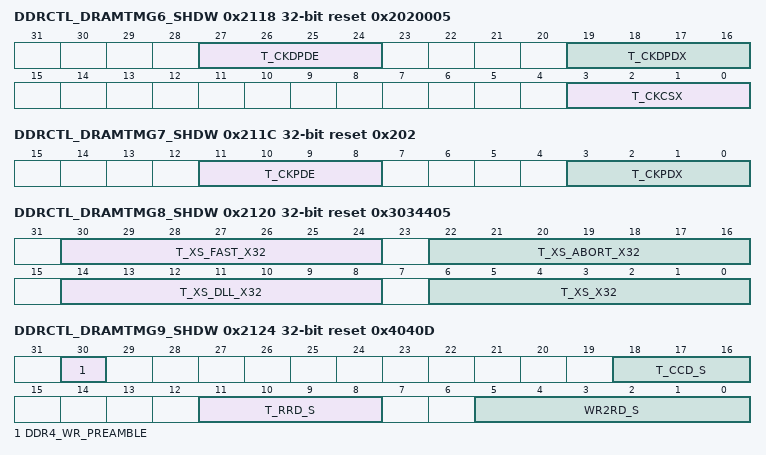
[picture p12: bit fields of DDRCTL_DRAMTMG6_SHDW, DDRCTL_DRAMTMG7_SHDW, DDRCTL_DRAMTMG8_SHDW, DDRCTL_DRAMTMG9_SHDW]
0x2118 DDRCTL_DRAMTMG6_SHDW reset 0x2020005 — [FREQ1] SDRAM Timing Register 6
  [27:24] T_CKDPDE — This is the time after Deep Power Down Entry that CK is maintained as a valid clock.
  [19:16] T_CKDPDX — This is the time before Deep Power Down Exit that CK is maintained as a valid clock before issuing DPDX.
  [3:0] T_CKCSX — This is the time before Clock Stop Exit that CK is maintained as a valid clock before issuing Clock Stop Exit.
0x211C DDRCTL_DRAMTMG7_SHDW reset 0x202 — [FREQ1] SDRAM Timing Register 7
  [11:8] T_CKPDE — This is the time after Power Down Entry that CK is maintained as a valid clock.
  [3:0] T_CKPDX — This is the time before Power Down Exit that CK is maintained as a valid clock before issuing PDX.
0x2120 DDRCTL_DRAMTMG8_SHDW reset 0x3034405 — [FREQ1] SDRAM Timing Register 8
  [30:24] T_XS_FAST_X32 — tXS_FAST: Exit Self Refresh to ZQCL, ZQCS and MRS (only CL, WR, RTP and Geardown mode).
  [22:16] T_XS_ABORT_X32 — tXS_ABORT: Exit Self Refresh to commands not requiring a locked DLL in Self Refresh Abort.
  [14:8] T_XS_DLL_X32 — tXSDLL: Exit Self Refresh to commands requiring a locked DLL.
  [6:0] T_XS_X32 — tXS: Exit Self Refresh to commands not requiring a locked DLL.
0x2124 DDRCTL_DRAMTMG9_SHDW reset 0x4040D — [FREQ1] SDRAM Timing Register 9
  [30] DDR4_WR_PREAMBLE — DDR4 Write preamble mode0 - 1tCK preamble1 - 2tCK preamble
  [18:16] T_CCD_S — tCCD_S: This is the minimum time between two reads or two writes for different bank group.
  [11:8] T_RRD_S — tRRD_S: Minimum time between activates from bank 'a' to bank 'b' for different bank group.
  [5:0] WR2RD_S — CWL + PL + BL/2 + tWTR_S Minimum time from write command to read command for different bank group.Where:- CWL = CAS write latency- PL = Parity latency- BL = burst length. This must match the value programmed in the BL bit of the mode register to the SDRAM- tWTR_S = internal write to read command delay for different bank group. This comes directly from the SDRAM specification.
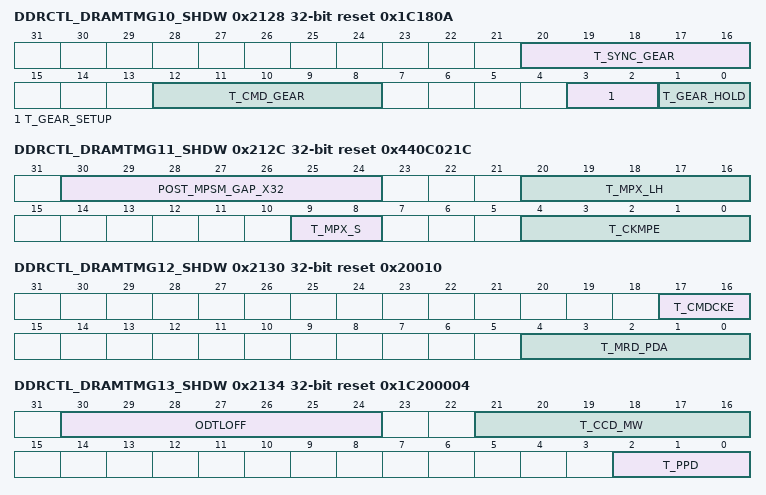
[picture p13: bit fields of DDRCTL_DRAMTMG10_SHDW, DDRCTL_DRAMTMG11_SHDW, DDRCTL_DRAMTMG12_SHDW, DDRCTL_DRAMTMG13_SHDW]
0x2128 DDRCTL_DRAMTMG10_SHDW reset 0x1C180A — [FREQ1] SDRAM Timing Register 10
  [20:16] T_SYNC_GEAR — Indicates the time between MRS command and the sync pulse time.
  [12:8] T_CMD_GEAR — Sync pulse to first valid command.
  [3:2] T_GEAR_SETUP — Geardown setup time.
  [1:0] T_GEAR_HOLD — Geardown hold time.
0x212C DDRCTL_DRAMTMG11_SHDW reset 0x440C021C — [FREQ1] SDRAM Timing Register 11
  [30:24] POST_MPSM_GAP_X32 — tXMPDLL: This is the minimum Exit MPSM to commands requiring a locked DLL.
  [20:16] T_MPX_LH — tMPX_LH: This is the minimum CS_n Low hold time to CKE rising edge.
  [9:8] T_MPX_S — tMPX_S: Minimum time CS setup time to CKE.
  [4:0] T_CKMPE — tCKMPE: Minimum valid clock requirement after MPSM entry.
0x2130 DDRCTL_DRAMTMG12_SHDW reset 0x20010 — [FREQ1] SDRAM Timing Register 12
  [17:16] T_CMDCKE — tCMDCKE: Delay from valid command to CKE input LOW.
  [4:0] T_MRD_PDA — tMRD_PDA: This is the Mode Register Set command cycle time in PDA mode.
0x2134 DDRCTL_DRAMTMG13_SHDW reset 0x1C200004 — [FREQ1] SDRAM Timing Register 13
  [30:24] ODTLOFF — LPDDR4: tODTLoff: This is the latency from CAS-2 command to tODToff reference.
  [21:16] T_CCD_MW — LPDDR4: tCCDMW: This is the minimum time from write or masked write to masked write command for same bank.
  [2:0] T_PPD — LPDDR4: tPPD: This is the minimum time from precharge to precharge command.
0x2138 DDRCTL_DRAMTMG14_SHDW reset 0xA0 — [FREQ1] SDRAM Timing Register 14
  [11:0] T_XSR — tXSR: Exit Self Refresh to any command.
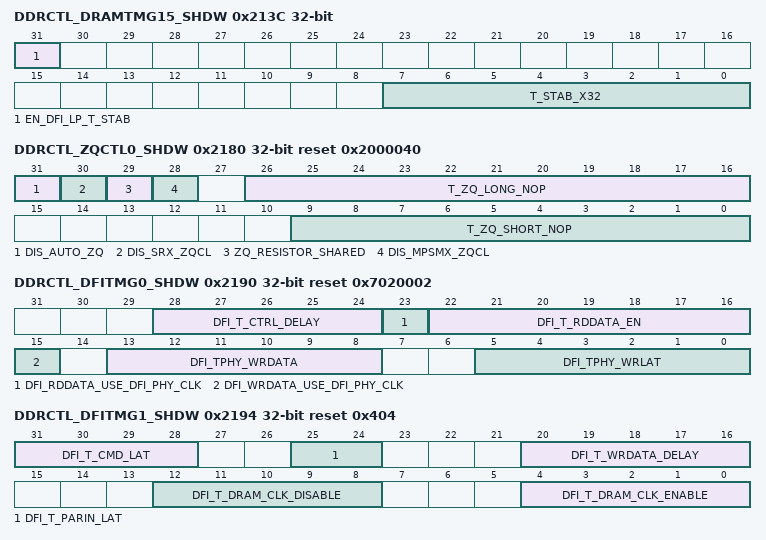
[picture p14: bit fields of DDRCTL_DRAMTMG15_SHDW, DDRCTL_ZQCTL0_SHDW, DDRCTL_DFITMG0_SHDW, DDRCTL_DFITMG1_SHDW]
0x213C DDRCTL_DRAMTMG15_SHDW — [FREQ1] SDRAM Timing Register 15
  [31] EN_DFI_LP_T_STAB — 1 - Enable using tSTAB when exiting DFI LP. Needs to be set when the PHY is stopping the clock during DFI LP to save maximum power.
  [7:0] T_STAB_X32 — tSTAB: Stabilization time.- when exiting power saving mode, if the clock was stopped, after re-enabling it the clock must be stable for a time specified by tSTAB- in the case of input clock frequency change (DDR4)- after issuing control words that refers to clock timing (Specification: 6us for DDR3, 5us for DDR4)
0x2180 DDRCTL_ZQCTL0_SHDW reset 0x2000040 — [FREQ1] ZQ Control Register 0
  [31] DIS_AUTO_ZQ — 1 - Disable DDR controller generation of ZQCS/MPC(ZQ calibration) command. Register DDRCTL_DBGCMD.zq_calib_short can be used instead to issue ZQ calibration request from APB module.
  [30] DIS_SRX_ZQCL — 1 - Disable issuing of ZQCL/MPC(ZQ calibration) command at Self-Refresh/SR-Powerdown exit. Only applicable when run in DDR3 or DDR4 or LPDDR2 or LPDDR3 or LPDDR4 mode.
  [29] ZQ_RESISTOR_SHARED — 1 - Denotes that ZQ resistor is shared between ranks. Means ZQinit/ZQCL/ZQCS/MPC(ZQ calibration) commands are sent to one rank at a time with tZQinit/tZQCL/tZQCS/tZQCAL/tZQLAT timing met between commands so that commands to different ranks do not overlap.
  [28] DIS_MPSMX_ZQCL — 1 - Disable issuing of ZQCL command at Maximum Power Saving Mode exit. Only applicable when run in DDR4 mode.
  [26:16] T_ZQ_LONG_NOP — tZQoper for DDR3/DDR4, tZQCL for LPDDR2/LPDDR3, tZQCAL for LPDDR4: Number of DDRSS_CTL_CLK clock cycles of NOP required after a ZQCL (ZQ calibration long)/MPC(ZQ Start) command is issued to SDRAM.DDR3/DDR4: program this to tZQoper/2 and round it up to the next integer value.LPDDR2/LPDDR3: program this to tZQCL/2 and round it up to the next integer value.LPDDR4: program this to tZQCAL/2 and round it up to the next integer value. This is only present for designs supporting DDR3/DDR4 or LPDDR2/LPDDR3/LPDDR4 devices.
  [9:0] T_ZQ_SHORT_NOP — tZQCS for DDR3/DD4/LPDDR2/LPDDR3, tZQLAT for LPDDR4: Number of DDRSS_CTL_CLK clock cycles of NOP required after a ZQCS (ZQ calibration short)/MPC(ZQ Latch) command is issued to SDRAM.
0x2190 DDRCTL_DFITMG0_SHDW reset 0x7020002 — [FREQ1] DFI Timing Register 0
  [28:24] DFI_T_CTRL_DELAY — Specifies the number of DDRSS_CTL_CLK clock cycles after an assertion or de-assertion of the DFI control signals that the control signals at the PHY-DRAM interface reflect the assertion or de-assertion.
  [23] DFI_RDDATA_USE_DFI_PHY_CLK — Defines whether dfi_rddata_en/dfi_rddata/dfi_rddata_valid is generated using HDR (DDRSS_CTL_CLK clock) or SDR (2 x DDRSS_CTL_CLK clock) values.- 0 in terms of HDR (DDRSS_CTL_CLK clock) cycles- 1 in terms of SDR (2 x DDRSS_CTL_CLK clock) cyclesIf using a DWC DDR3/2 PHY, DWC DDR2/3-Lite/mDDR PHY, DWC DDR multiPHY or DWC Gen2 DDR multiPHY, this field must be set to 0 otherwise, it must be set to 1.Programming Mode: Static
  [22:16] DFI_T_RDDATA_EN — Time from the assertion of a read command on the DFI interface to the assertion of the dfi_rddata_en signal. This corresponds to the DFI parameter trddata_en.
  [15] DFI_WRDATA_USE_DFI_PHY_CLK — Defines whether dfi_wrdata_en/dfi_wrdata/dfi_wrdata_mask is generated using HDR (DDRSS_CTL_CLK clock) or SDR (2 x DDRSS_CTL_CLK clock) values Selects whether value in DDRCTL_DFITMG0. dfi_tphy_wrlat is in terms of HDR (DDRSS_CTL_CLK clock) or SDR (2 x DDRSS_CTL_CLK clock) cycles Selects whether value in DDRCTL_DFITMG0.dfi_tphy_wrdata is in terms of HDR (DDRSS_CTL_CLK clock) or SDR (2 x DDRSS_CTL_CLK clock) cycles- 0 in terms of HDR (DDRSS_CTL_CLK clock) cycles- 1 in terms of SDR (2 x DDRSS_CTL_CLK clock) cyclesIf using a DWC DDR3/2 PHY, DWC DDR2/3-Lite/mDDR PHY, DWC DDR multiPHY or DWC Gen2 DDR multiPHY, this field must be set to 0 otherwise, it must be set to 1.Programming Mode: Static
  [13:8] DFI_TPHY_WRDATA — Specifies the number of clock cycles between when dfi_wrdata_en is asserted to when the associated write data is driven on the dfi_wrdata signal.
  [5:0] DFI_TPHY_WRLAT — Write latency Number of clocks from the write command to write data enable (dfi_wrdata_en). This corresponds to the DFI timing parameter tphy_wrlat.
0x2194 DDRCTL_DFITMG1_SHDW reset 0x404 — [FREQ1] DFI Timing Register 1
  fields as DDRCTL_DFITMG1
0x21B4 DDRCTL_DFITMG2_SHDW reset 0x202 — [FREQ1] DFI Timing Register 2
  fields as DDRCTL_DFITMG2
0x21B8 DDRCTL_DFITMG3_SHDW — [FREQ1] DFI Timing Register 3
  fields as DDRCTL_DFITMG3
0x2240 DDRCTL_ODTCFG_SHDW reset 0x4000400 — [FREQ1] ODT Configuration Register
  [27:24] WR_ODT_HOLD — 2 x DDRSS_CTL_CLK clock cycles to hold ODT for a write command.DDR2:- BL8: 0x5 (DDR2-400/533/667), 0x6 (DDR2-800), 0x7 (DDR2-1066)- BL4: 0x3 (DDR2-400/533/667), 0x4 (DDR2-800), 0x5 (DDR2-1066)DDR3:- BL8: 0x6DDR4:- BL8: 5 + WR_PREAMBLE + CRC_MODE WR_PREAMBLE = 1 (1tCK write preamble), 2 (2tCK write preamble) CRC_MODE = 0 (not CRC mode), 1 (CRC mode)LPDDR3:- BL8: 7 + RU(tODTon(max)/tCK)
  [20:16] WR_ODT_DELAY — The delay, in 2 x DDRSS_CTL_CLK clock cycles, from issuing a write command to setting ODT values associated with that command.DDR2:- CWL + AL - 3 (DDR2-400/533/667),- CWL + AL - 4 (DDR2-800),- CWL + AL - 5 (DDR2-1066)If (CWL + AL - 3 &lt; 0), DDR controller does not support ODT for write operation.DDR3: 0x0DDR4: DDRCTL_DFITMG1.dfi_t_cmd_lat (to adjust for CAL mode)LPDDR3: WL - 1 - RU(tODTon(max)/tCK)
  [11:8] RD_ODT_HOLD — 2 x DDRSS_CTL_CLK clock cycles to hold ODT for a read command.DDR2:- BL8: 0x6 (not DDR2-1066), 0x7 (DDR2-1066)- BL4: 0x4 (not DDR2-1066), 0x5 (DDR2-1066)DDR3:- BL8: 0x6DDR4:- BL8: 5 + RD_PREAMBLE RD_PREAMBLE = 1 (1tCK write preamble), 2 (2tCK write preamble)LPDDR3:- BL8: 5 + RU(tDQSCK(max)/tCK) - RD(tDQSCK(min)/tCK) + RU(tODTon(max)/tCK)
  [6:2] RD_ODT_DELAY — The delay, in 2 x DDRSS_CTL_CLK clock cycles, from issuing a read command to setting ODT values associated with that command.DDR2:- CL + AL - 4 (not DDR2-1066)- CL + AL - 5 (DDR2-1066)If (CL + AL - 4 &lt; 0), DDR controller does not support ODT for read operation.DDR3: CL - CWLDDR4: CL - CWL - RD_PREAMBLE + WR_PREAMBLE + DDRCTL_DFITMG1.dfi_t_cmd_lat (to adjust for CAL mode) WR_PREAMBLE = 1 (1tCK write preamble), 2 (2tCK write preamble) RD_PREAMBLE = 1 (1tCK write preamble), 2 (2tCK write preamble).If (CL - CWL - RD_PREAMBLE + WR_PREAMBLE) &lt; 0, DDR controller does not support ODT for read operation.LPDDR3: RL + RD(tDQSCK(min)/tCK) - 1 - RU(tODTon(max)/tCK)
